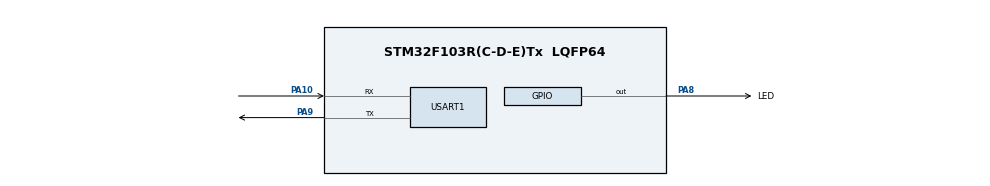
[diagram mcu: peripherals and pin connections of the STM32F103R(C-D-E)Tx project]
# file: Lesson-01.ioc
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Mcu.Family=STM32F1
Mcu.Name=STM32F103R(C-D-E)Tx
Mcu.Package=LQFP64
NVIC.PriorityGroup=NVIC_PRIORITYGROUP_4
PA10.Mode=Asynchronous
PA10.Signal=USART1_RX
PA13.Mode=Serial_Wire
PA13.Signal=SYS_JTMS-SWDIO
PA14.Mode=Serial_Wire
PA14.Signal=SYS_JTCK-SWCLK
PA8.GPIO_Label=LED
PA8.Signal=GPIO_Output
PA9.Mode=Asynchronous
PA9.Signal=USART1_TX
ProjectManager.HeapSize=0x200
ProjectManager.StackSize=0x400
ProjectManager.TargetToolchain=MDK-ARM V5
RCC.APB1Freq_Value=8000000
RCC.APB2Freq_Value=8000000
USART1.VirtualMode=VM_ASYNC
board=custom

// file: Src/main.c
/* USER CODE BEGIN Header */
/**
  ******************************************************************************
  * @file           : main.c
  * @brief          : Main program body
  ******************************************************************************
  * @attention
  *
  * <h2><center>&copy; Copyright (c) 2020 STMicroelectronics.
  * All rights reserved.</center></h2>
  *
  * This software component is licensed by ST under BSD 3-Clause license,
  * the "License"; You may not use this file except in compliance with the
  * License. You may obtain a copy of the License at:
  *                        opensource.org/licenses/BSD-3-Clause
  *
  ******************************************************************************
  */
/* USER CODE END Header */

#include "main.h"
#include "usart.h"
#include "gpio.h"

/* USER CODE BEGIN Includes */
#include <stdio.h>
/* USER CODE END Includes */

void SystemClock_Config(void);

int main(void)
{

  /* MCU Configuration--------------------------------------------------------*/

  /* Reset of all peripherals, Initializes the Flash interface and the Systick. */
  HAL_Init();

  /* Configure the system clock */
  SystemClock_Config();

  /* Initialize all configured peripherals */
  MX_GPIO_Init();
  MX_USART1_UART_Init();

  /* Infinite loop */
  while (1)
  {

    /* USER CODE BEGIN 3 */
		/************采用读写IO的方式翻转IO口电平*****************/
		GPIO_PinState state = HAL_GPIO_ReadPin(LED_GPIO_Port,LED_Pin);
		if(state != GPIO_PIN_SET){
			HAL_GPIO_WritePin(LED_GPIO_Port,LED_Pin,GPIO_PIN_SET);
			HAL_Delay(1000);
		} else {
			HAL_GPIO_WritePin(LED_GPIO_Port,LED_Pin,GPIO_PIN_RESET);
			HAL_Delay(1000);
		}

//		GPIO_PinState state2 = HAL_GPIO_ReadPin(LED_GPIO_Port,LED_Pin);
//		HAL_GPIO_WritePin(LED_GPIO_Port,LED_Pin,!state2);
//		HAL_Delay(1000);
//
//		/************直接用Toggle函数翻转IO口电平*****************/
//		HAL_GPIO_TogglePin(LED_GPIO_Port,LED_Pin);
//		HAL_Delay(1000);

		/********串口输出打印测试*********/
		printf("d = %d - %d\r\n",48,67); // 10进制
		printf("x = 0x%x \r\n",48); // 16进制
		printf("f = %f \r\n",28.5); // float浮点数
		printf("%s \r\n","num = 34.5% "); // 字符串
		HAL_Delay(3000);

  }
  /* USER CODE END 3 */
}

void SystemClock_Config(void)
{
  RCC_OscInitTypeDef RCC_OscInitStruct = {0};
  RCC_ClkInitTypeDef RCC_ClkInitStruct = {0};

  /** Initializes the CPU, AHB and APB busses clocks
  */
  RCC_OscInitStruct.OscillatorType = RCC_OSCILLATORTYPE_HSI;
  RCC_OscInitStruct.HSIState = RCC_HSI_ON;
  RCC_OscInitStruct.HSICalibrationValue = RCC_HSICALIBRATION_DEFAULT;
  RCC_OscInitStruct.PLL.PLLState = RCC_PLL_NONE;
  if (HAL_RCC_OscConfig(&RCC_OscInitStruct) != HAL_OK)
  {
    Error_Handler();
  }
  /** Initializes the CPU, AHB and APB busses clocks
  */
  RCC_ClkInitStruct.ClockType = RCC_CLOCKTYPE_HCLK|RCC_CLOCKTYPE_SYSCLK
                              |RCC_CLOCKTYPE_PCLK1|RCC_CLOCKTYPE_PCLK2;
  RCC_ClkInitStruct.SYSCLKSource = RCC_SYSCLKSOURCE_HSI;
  RCC_ClkInitStruct.AHBCLKDivider = RCC_SYSCLK_DIV1;
  RCC_ClkInitStruct.APB1CLKDivider = RCC_HCLK_DIV1;
  RCC_ClkInitStruct.APB2CLKDivider = RCC_HCLK_DIV1;

  if (HAL_RCC_ClockConfig(&RCC_ClkInitStruct, FLASH_LATENCY_0) != HAL_OK)
  {
    Error_Handler();
  }
}

/* USER CODE BEGIN 4 */
/************串口重定向函数*****************/
// print charactors with UART1
int fputc(int ch , FILE *f)
{
	HAL_UART_Transmit(&huart1, (uint8_t *)&ch , 1 , 0xFFFF);
	return ch;
}
/* USER CODE END 4 */

void Error_Handler(void)
{
}

/************************ (C) COPYRIGHT STMicroelectronics *****END OF FILE****/
